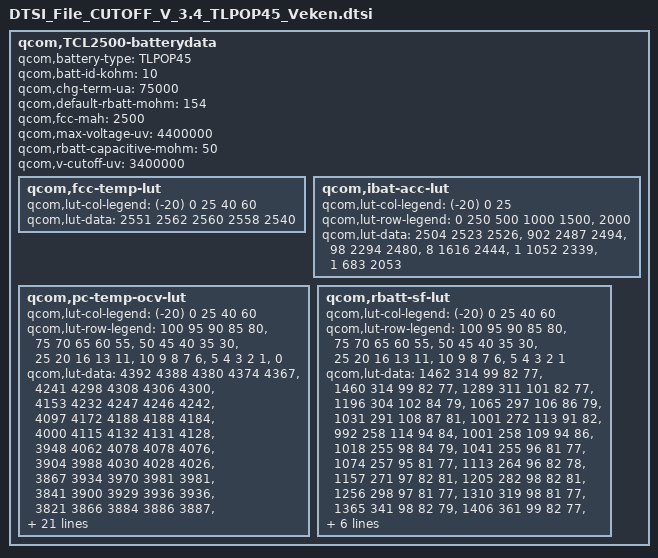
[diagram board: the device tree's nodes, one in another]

qcom,TCL2500-batterydata {
	qcom,battery-type = "TLPOP45";
	qcom,batt-id-kohm = <10>;
	qcom,chg-term-ua = <75000>;
	qcom,default-rbatt-mohm = <154>;
	qcom,fcc-mah = <2500>;
	qcom,max-voltage-uv = <4400000>;
	qcom,rbatt-capacitive-mohm = <50>;
	qcom,v-cutoff-uv = <3400000>;

	qcom,fcc-temp-lut {
		qcom,lut-col-legend = <(-20) 0 25 40 60>;
		qcom,lut-data = <2551 2562 2560 2558 2540>;
	};

	qcom,ibat-acc-lut {
		qcom,lut-col-legend = <(-20) 0 25>;
		qcom,lut-row-legend = <0 250 500 1000 1500>,
					<2000>;
		qcom,lut-data = <2504 2523 2526>,
				<902 2487 2494>,
				<98 2294 2480>,
				<8 1616 2444>,
				<1 1052 2339>,
				<1 683 2053>;
	};

	qcom,pc-temp-ocv-lut {
		qcom,lut-col-legend = <(-20) 0 25 40 60>;
		qcom,lut-row-legend = <100 95 90 85 80>,
					<75 70 65 60 55>,
					<50 45 40 35 30>,
					<25 20 16 13 11>,
					<10 9 8 7 6>,
					<5 4 3 2 1>,
					<0>;
		qcom,lut-data = <4392 4388 4380 4374 4367>,
				<4241 4298 4308 4306 4300>,
				<4153 4232 4247 4246 4242>,
				<4097 4172 4188 4188 4184>,
				<4000 4115 4132 4131 4128>,
				<3948 4062 4078 4078 4076>,
				<3904 3988 4030 4028 4026>,
				<3867 3934 3970 3981 3981>,
				<3841 3900 3929 3936 3936>,
				<3821 3866 3884 3886 3887>,
				<3804 3836 3850 3851 3850>,
				<3789 3812 3824 3825 3826>,
				<3774 3793 3803 3804 3804>,
				<3760 3778 3785 3785 3785>,
				<3744 3766 3770 3767 3765>,
				<3725 3752 3756 3748 3738>,
				<3702 3734 3738 3730 3716>,
				<3680 3718 3720 3710 3698>,
				<3658 3704 3700 3690 3678>,
				<3644 3696 3690 3682 3670>,
				<3633 3692 3688 3680 3669>,
				<3620 3686 3686 3679 3668>,
				<3608 3680 3684 3677 3666>,
				<3592 3672 3680 3674 3662>,
				<3572 3659 3674 3666 3653>,
				<3548 3638 3656 3646 3630>,
				<3520 3601 3618 3603 3586>,
				<3478 3543 3558 3543 3526>,
				<3416 3453 3474 3458 3444>,
				<3310 3286 3338 3325 3314>,
				<3000 3000 3000 3000 3000>;
	};

	qcom,rbatt-sf-lut {
		qcom,lut-col-legend = <(-20) 0 25 40 60>;
		qcom,lut-row-legend = <100 95 90 85 80>,
					<75 70 65 60 55>,
					<50 45 40 35 30>,
					<25 20 16 13 11>,
					<10 9 8 7 6>,
					<5 4 3 2 1>;
		qcom,lut-data = <1462 314 99 82 77>,
				<1460 314 99 82 77>,
				<1289 311 101 82 77>,
				<1196 304 102 84 79>,
				<1065 297 106 86 79>,
				<1031 291 108 87 81>,
				<1001 272 113 91 82>,
				<992 258 114 94 84>,
				<1001 258 109 94 86>,
				<1018 255 98 84 79>,
				<1041 255 96 81 77>,
				<1074 257 95 81 77>,
				<1113 264 96 82 78>,
				<1157 271 97 82 81>,
				<1205 282 98 82 81>,
				<1256 298 97 81 77>,
				<1310 319 98 81 77>,
				<1365 341 98 82 79>,
				<1406 361 99 82 77>,
				<1412 370 98 81 77>,
				<1440 383 99 83 78>,
				<1472 398 100 84 81>,
				<1556 414 103 87 82>,
				<1677 438 106 90 84>,
				<1843 461 110 92 86>,
				<2052 487 110 89 84>,
				<2374 514 107 86 82>,
				<2861 557 109 87 82>,
				<3715 627 113 91 84>,
				<5462 1253 153 176 103>;
	};
};
/* TEST_DB_ID=TEST_ID_NOT_SET */
